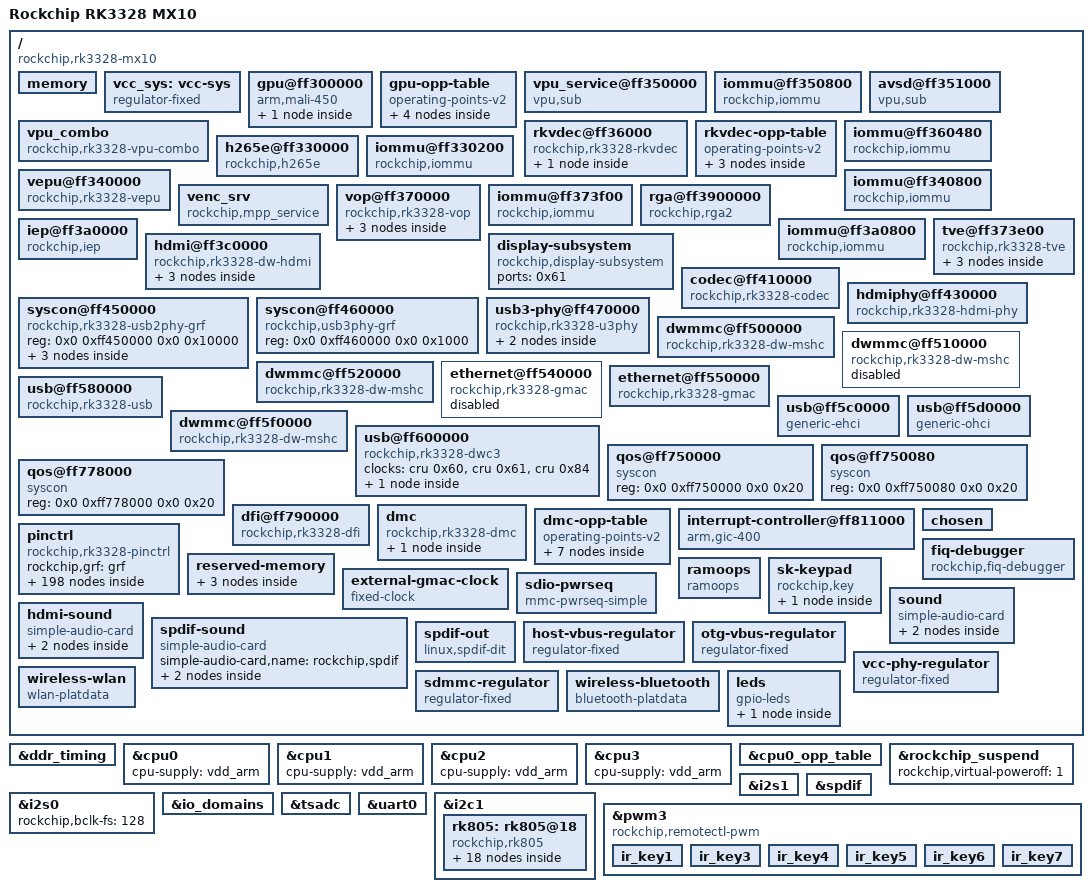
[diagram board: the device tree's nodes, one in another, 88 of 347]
/dts-v1/;

/memreserve/	0x0000000004600000 0x0000000000010000;
/memreserve/	0x0000000004bf0000 0x000000000016c4d8;

#include <dt-bindings/input/input.h>
#include "rk3328_tmp.dtsi"

&ddr_timing {
		ddr3a1_ddr4a9_de-skew = <0x2>;
		ddr3a0_ddr4a10_de-skew = <0x3>;
		ddr3a3_ddr4a6_de-skew = <0x3>;
		ddr3a2_ddr4a4_de-skew = <0x2>;
		ddr3a5_ddr4a8_de-skew = <0x3>;
		ddr3a4_ddr4a5_de-skew = <0x2>;
		ddr3a7_ddr4a11_de-skew = <0x3>;
		ddr3a6_ddr4a7_de-skew = <0x2>;
		ddr3a9_ddr4a0_de-skew = <0x2>;
		ddr3a8_ddr4a13_de-skew = <0x1>;
		ddr3a11_ddr4a3_de-skew = <0x2>;
		ddr3a10_ddr4cs0_de-skew = <0x2>;
		ddr3a13_ddr4a2_de-skew = <0x1>;
		ddr3a12_ddr4ba1_de-skew = <0x2>;
		ddr3a15_ddr4odt0_de-skew = <0x3>;
		ddr3a14_ddr4a1_de-skew = <0x2>;
		ddr3ba1_ddr4a15_de-skew = <0x2>;
		ddr3ba0_ddr4bg0_de-skew = <0x4>;
		ddr3ras_ddr4cke_de-skew = <0x4>;
		ddr3ba2_ddr4ba0_de-skew = <0x3>;
		ddr3we_ddr4bg1_de-skew = <0x2>;
		ddr3cas_ddr4a12_de-skew = <0x2>;
		ddr3ckn_ddr4ckn_de-skew = <0x7>;
		ddr3ckp_ddr4ckp_de-skew = <0x7>;
		ddr3cke_ddr4a16_de-skew = <0x2>;
		ddr3odt0_ddr4a14_de-skew = <0x4>;
		ddr3cs0_ddr4act_de-skew = <0x4>;		
		ddr3reset_ddr4reset_de-skew = <0x7>;
		ddr3cs1_ddr4cs1_de-skew = <0x7>;
		ddr3odt1_ddr4odt1_de-skew = <0x7>;
		cs0_dm0_rx_de-skew = <0xc>;
		cs0_dm0_tx_de-skew = <0xa>;
		cs0_dq0_rx_de-skew = <0xc>;
		cs0_dq0_tx_de-skew = <0xa>;
		cs0_dq1_rx_de-skew = <0xc>;
		cs0_dq1_tx_de-skew = <0xa>;
		cs0_dq2_rx_de-skew = <0xc>;
		cs0_dq2_tx_de-skew = <0xa>;
		cs0_dq3_rx_de-skew = <0xc>;
		cs0_dq3_tx_de-skew = <0xa>;
		cs0_dq4_rx_de-skew = <0xc>;
		cs0_dq4_tx_de-skew = <0xa>;
		cs0_dq5_rx_de-skew = <0xc>;
		cs0_dq5_tx_de-skew = <0xa>;
		cs0_dq6_rx_de-skew = <0xc>;
		cs0_dq6_tx_de-skew = <0xa>;
		cs0_dq7_rx_de-skew = <0xc>;
		cs0_dq7_tx_de-skew = <0xa>;
		cs0_dqs0_rx_de-skew = <0xa>;
		cs0_dqs0p_tx_de-skew = <0xb>;
		cs0_dqs0n_tx_de-skew = <0xb>;
		cs0_dm1_rx_de-skew = <0xa>;
		cs0_dm1_tx_de-skew = <0x8>;
		cs0_dq8_rx_de-skew = <0xa>;
		cs0_dq8_tx_de-skew = <0x8>;
		cs0_dq9_rx_de-skew = <0xa>;
		cs0_dq9_tx_de-skew = <0x8>;
		cs0_dq10_rx_de-skew = <0xa>;
		cs0_dq10_tx_de-skew = <0x8>;
		cs0_dq11_rx_de-skew = <0xa>;
		cs0_dq11_tx_de-skew = <0x8>;
		cs0_dq12_rx_de-skew = <0xa>;
		cs0_dq12_tx_de-skew = <0x8>;
		cs0_dq13_rx_de-skew = <0xa>;
		cs0_dq13_tx_de-skew = <0x8>;
		cs0_dq14_rx_de-skew = <0xa>;
		cs0_dq14_tx_de-skew = <0x8>;
		cs0_dq15_rx_de-skew = <0xa>;
		cs0_dq15_tx_de-skew = <0x8>;
		cs0_dqs1_rx_de-skew = <0x9>;
		cs0_dqs1p_tx_de-skew = <0x8>;
		cs0_dqs1n_tx_de-skew = <0x8>;
		cs0_dm2_rx_de-skew = <0xa>;
		cs0_dm2_tx_de-skew = <0x9>;
		cs0_dq16_rx_de-skew = <0xa>;
		cs0_dq16_tx_de-skew = <0x9>;
		cs0_dq17_rx_de-skew = <0xa>;
		cs0_dq17_tx_de-skew = <0x9>;
		cs0_dq18_rx_de-skew = <0xa>;
		cs0_dq18_tx_de-skew = <0x9>;
		cs0_dq19_rx_de-skew = <0xa>;
		cs0_dq19_tx_de-skew = <0x9>;
		cs0_dq20_rx_de-skew = <0xa>;
		cs0_dq20_tx_de-skew = <0x9>;
		cs0_dq21_rx_de-skew = <0xa>;
		cs0_dq21_tx_de-skew = <0x9>;
		cs0_dq22_rx_de-skew = <0xa>;
		cs0_dq22_tx_de-skew = <0x9>;
		cs0_dq23_rx_de-skew = <0xa>;
		cs0_dq23_tx_de-skew = <0x9>;
		cs0_dqs2_rx_de-skew = <0x9>;
		cs0_dqs2p_tx_de-skew = <0x9>;
		cs0_dqs2n_tx_de-skew = <0x9>;
		cs0_dm3_rx_de-skew = <0x7>;
		cs0_dm3_tx_de-skew = <0x7>;
		cs0_dq24_rx_de-skew = <0x7>;
		cs0_dq24_tx_de-skew = <0x7>;
		cs0_dq25_rx_de-skew = <0x7>;
		cs0_dq25_tx_de-skew = <0x7>;
		cs0_dq26_rx_de-skew = <0x7>;
		cs0_dq26_tx_de-skew = <0x7>;
		cs0_dq27_rx_de-skew = <0x7>;
		cs0_dq27_tx_de-skew = <0x7>;
		cs0_dq28_rx_de-skew = <0x7>;
		cs0_dq28_tx_de-skew = <0x7>;
		cs0_dq29_rx_de-skew = <0x7>;
		cs0_dq29_tx_de-skew = <0x7>;
		cs0_dq30_rx_de-skew = <0x7>;
		cs0_dq30_tx_de-skew = <0x7>;
		cs0_dq31_rx_de-skew = <0x7>;
		cs0_dq31_tx_de-skew = <0x7>;
		cs0_dqs3_rx_de-skew = <0x7>;
		cs0_dqs3p_tx_de-skew = <0x8>;
		cs0_dqs3n_tx_de-skew = <0x8>;
		cs1_dm0_rx_de-skew = <0x7>;
		cs1_dm0_tx_de-skew = <0x8>;
		cs1_dq0_rx_de-skew = <0x7>;
		cs1_dq0_tx_de-skew = <0x8>;
		cs1_dq1_rx_de-skew = <0x7>;
		cs1_dq1_tx_de-skew = <0x8>;
		cs1_dq2_rx_de-skew = <0x7>;
		cs1_dq2_tx_de-skew = <0x8>;
		cs1_dq3_rx_de-skew = <0x7>;
		cs1_dq3_tx_de-skew = <0x8>;
		cs1_dq4_rx_de-skew = <0x7>;
		cs1_dq4_tx_de-skew = <0x8>;
		cs1_dq5_rx_de-skew = <0x7>;
		cs1_dq5_tx_de-skew = <0x8>;
		cs1_dq6_rx_de-skew = <0x7>;
		cs1_dq6_tx_de-skew = <0x8>;
		cs1_dq7_rx_de-skew = <0x7>;
		cs1_dq7_tx_de-skew = <0x8>;
		cs1_dqs0_rx_de-skew = <0x6>;
		cs1_dqs0p_tx_de-skew = <0x9>;
		cs1_dqs0n_tx_de-skew = <0x9>;
		cs1_dm1_rx_de-skew = <0x7>;
		cs1_dm1_tx_de-skew = <0x7>;
		cs1_dq8_rx_de-skew = <0x7>;
		cs1_dq8_tx_de-skew = <0x8>;
		cs1_dq9_rx_de-skew = <0x7>;
		cs1_dq9_tx_de-skew = <0x7>;
		cs1_dq10_rx_de-skew = <0x7>;
		cs1_dq10_tx_de-skew = <0x8>;
		cs1_dq11_rx_de-skew = <0x7>;
		cs1_dq11_tx_de-skew = <0x7>;
		cs1_dq12_rx_de-skew = <0x7>;
		cs1_dq12_tx_de-skew = <0x8>;
		cs1_dq13_rx_de-skew = <0x7>;
		cs1_dq13_tx_de-skew = <0x7>;
		cs1_dq14_rx_de-skew = <0x7>;
		cs1_dq14_tx_de-skew = <0x8>;
		cs1_dq15_rx_de-skew = <0x7>;
		cs1_dq15_tx_de-skew = <0x7>;
		cs1_dqs1_rx_de-skew = <0x7>;
		cs1_dqs1p_tx_de-skew = <0x9>;
		cs1_dqs1n_tx_de-skew = <0x9>;
		cs1_dm2_rx_de-skew = <0x7>;
		cs1_dm2_tx_de-skew = <0x8>;
		cs1_dq16_rx_de-skew = <0x7>;
		cs1_dq16_tx_de-skew = <0x8>;
		cs1_dq17_rx_de-skew = <0x7>;
		cs1_dq17_tx_de-skew = <0x8>;
		cs1_dq18_rx_de-skew = <0x7>;
		cs1_dq18_tx_de-skew = <0x8>;
		cs1_dq19_rx_de-skew = <0x7>;
		cs1_dq19_tx_de-skew = <0x8>;
		cs1_dq20_rx_de-skew = <0x7>;
		cs1_dq20_tx_de-skew = <0x8>;
		cs1_dq21_rx_de-skew = <0x7>;
		cs1_dq21_tx_de-skew = <0x8>;
		cs1_dq22_rx_de-skew = <0x7>;
		cs1_dq22_tx_de-skew = <0x8>;
		cs1_dq23_rx_de-skew = <0x7>;
		cs1_dq23_tx_de-skew = <0x8>;
		cs1_dqs2_rx_de-skew = <0x6>;
		cs1_dqs2p_tx_de-skew = <0x9>;
		cs1_dqs2n_tx_de-skew = <0x9>;
		cs1_dm3_rx_de-skew = <0x7>;
		cs1_dm3_tx_de-skew = <0x7>;
		cs1_dq24_rx_de-skew = <0x7>;
		cs1_dq24_tx_de-skew = <0x8>;
		cs1_dq25_rx_de-skew = <0x7>;
		cs1_dq25_tx_de-skew = <0x7>;
		cs1_dq26_rx_de-skew = <0x7>;
		cs1_dq26_tx_de-skew = <0x7>;
		cs1_dq27_rx_de-skew = <0x7>;
		cs1_dq27_tx_de-skew = <0x7>;
		cs1_dq28_rx_de-skew = <0x7>;
		cs1_dq28_tx_de-skew = <0x7>;
		cs1_dq29_rx_de-skew = <0x7>;
		cs1_dq29_tx_de-skew = <0x7>;
		cs1_dq30_rx_de-skew = <0x7>;
		cs1_dq30_tx_de-skew = <0x7>;
		cs1_dq31_rx_de-skew = <0x7>;
		cs1_dq31_tx_de-skew = <0x7>;
		cs1_dqs3_rx_de-skew = <0x7>;
		cs1_dqs3p_tx_de-skew = <0x9>;
		cs1_dqs3n_tx_de-skew = <0x9>;
};

&cpu0 {
	cpu-supply = <&vdd_arm>;
};

&cpu1 {
	cpu-supply = <&vdd_arm>;
};

&cpu2 {
	cpu-supply = <&vdd_arm>;
};

&cpu3 {
	cpu-supply = <&vdd_arm>;
};

&cpu0_opp_table{
	rockchip,leakage-voltage-sel = <0x1 0x8 0x0 0x9 0xfe 0x1>;
};

&rockchip_suspend {
	rockchip,virtual-poweroff = <1>;
	status = "okay";
};

&i2s0{
	#sound-dai-cells = <0>;
	rockchip,bclk-fs = <128>;
	status = "okay";
};

&i2s1{
	#sound-dai-cells = <0>;
	status = "okay";
};

&spdif {
	#sound-dai-cells = <0>;
	status = "okay";
};

&io_domains {
	status = "okay";
	
	vccio1-supply = <&vcc_io>;
	vccio2-supply = <&vcc18_emmc>;
	vccio3-supply = <&vcc_io>;
	vccio4-supply = <&vcc_18>;		// to be verified!
	vccio5-supply = <&vcc_io>;
	vccio6-supply = <&vcc_io>;
	pmuio-supply = <&vcc_io>;
};

&tsadc{
	status = "okay";
};

&uart0 {
	status = "okay";
};

&i2c1 {
	status = "okay";

	rk805: rk805@18 {
		compatible = "rockchip,rk805";
		status = "okay";
		reg = <0x18>;
		interrupt-parent = <0x3e>;		//interrupt-parent = <&gpio2>;
		interrupts = <0x6 0x8>;
		#clock-cells = <1>;
		clock-output-names = "xin32k", "rk805-clkout2";
		pinctrl-names = "default";
		pinctrl-0 = <0x3f>;			//pinctrl-0 = <&pmic_int_l>;
		wakeup-source;
		gpio-controller;
		#gpio-cells = <2>;

		//vcc1-supply = <&vcc_sys>;
		//vcc2-supply = <&vcc_sys>;
		//vcc3-supply = <&vcc_sys>;
		//vcc4-supply = <&vcc_sys>;
		//vcc5-supply = <&vcc_io>;
		//vcc6-supply = <&vcc_sys>;

		rtc {
			status = "okay";
		};

		pwrkey {
			status = "disabled";
		};
		gpio {
			status = "okay";
		};

		regulators {
			compatible = "rk805-regulator";
			status = "okay";
			#address-cells = <1>;
			#size-cells = <0>;
			
			vdd_logic: RK805_DCDC1 {
				regulator-compatible = "RK805_DCDC1";
				regulator-name = "vdd_logic";
				regulator-min-microvolt = <712500>;
				regulator-max-microvolt = <1450000>;
				regulator-initial-mode = <1>;
				regulator-ramp-delay = <12500>;
				regulator-always-on;
				regulator-boot-on;
				regulator-state-mem {
					regulator-mode = <0x2>;
					regulator-on-in-suspend;
					regulator-suspend-microvolt = <1000000>;
				};
			};

			vdd_arm: RK805_DCDC2 {
				regulator-compatible = "RK805_DCDC2";
				regulator-name = "vdd_arm";
				regulator-init-microvolt = <1225000>;
				regulator-min-microvolt = <712500>;
				regulator-max-microvolt = <1450000>;
				regulator-initial-mode = <0x1>;
				regulator-ramp-delay = <12500>;
				regulator-always-on;
				regulator-boot-on;				
				regulator-state-mem {
					regulator-mode = <0x2>;
					regulator-on-in-suspend;
					regulator-suspend-microvolt = <950000>;
				};
			};
			
			vcc_ddr: RK805_DCDC3 {
				regulator-compatible = "RK805_DCDC3";
				regulator-name = "vcc_ddr";
				regulator-initial-mode = <0x1>;
				regulator-always-on;
				regulator-boot-on;				
				regulator-state-mem {
					regulator-mode = <0x2>;
					regulator-on-in-suspend;
				};
			};

			vcc_io: RK805_DCDC4 {
				regulator-compatible = "RK805_DCDC4";
				regulator-name = "vcc_io";
				regulator-min-microvolt = <3300000>;
				regulator-max-microvolt = <3300000>;
				regulator-initial-mode = <0x1>;
				regulator-always-on;
				regulator-boot-on;				
				regulator-state-mem {
					regulator-mode = <0x2>;
					regulator-on-in-suspend;
					regulator-suspend-microvolt = <3300000>;
				};
			};

			vcc_18: RK805_LDO1 {
				regulator-compatible = "RK805_LDO1";
				regulator-name = "vdd_18";
				regulator-min-microvolt = <1800000>;
				regulator-max-microvolt = <1800000>;
				regulator-always-on;
				regulator-boot-on;				
				regulator-state-mem {
					regulator-on-in-suspend;
					regulator-suspend-microvolt = <1800000>;
				};
			};
			vcc18_emmc: RK805_LDO2 {
				regulator-compatible = "RK805_LDO2";
				regulator-name = "vcc_18emmc";
				regulator-min-microvolt = <1800000>;
				regulator-max-microvolt = <1800000>;
				regulator-always-on;
				regulator-boot-on;				
				regulator-state-mem {
					regulator-on-in-suspend;
					regulator-suspend-microvolt = <1800000>;
				};
			};
			vdd_11: RK805_LDO3 {
				regulator-compatible = "RK805_LDO3";
				regulator-name = "vdd_11";
				regulator-min-microvolt = <1100000>;
				regulator-max-microvolt = <1100000>;
				regulator-boot-on;
				regulator-always-on;
				regulator-state-mem {
					regulator-on-in-suspend;
					regulator-suspend-microvolt = <1100000>;
				};
			};
		};
	};
};

&pwm3 {
	status = "okay";
	compatible = "rockchip,remotectl-pwm";
	remote_pwm_id = <3>;
	handle_cpu_id = <1>;
	remote_support_psci = <1>;

	ir_key1 {
		rockchip,usercode = <0x4040>;
		rockchip,key_table =			//from rk3328-evb.dts
		<0xf2	KEY_REPLY>, 
		<0xba   KEY_BACK>,
		<0xf4   KEY_UP>,
		<0xf1   KEY_DOWN>,
		<0xef   KEY_LEFT>,
		<0xee   KEY_RIGHT>,
		<0xbd   KEY_HOME>,
		<0xea   KEY_VOLUMEUP>,
		<0xe3   KEY_VOLUMEDOWN>,
		<0xe2   KEY_SEARCH>,
		<0xb2   KEY_POWER>,
		<0xbc   KEY_MUTE>,
		<0xec   KEY_MENU>,
		<0xbf   0x190>,
		<0xe0   0x191>,
		<0xe1   0x192>,
		<0xe9   183>,
		<0xe6   248>,
		<0xe8   185>,
		<0xe7   186>,
		<0xf0   388>,
		<0xbe   0x175>;
	};

	ir_key3 {
		rockchip,usercode = <0x1dcc>;
		rockchip,key_table = <0xee 0xe8 0xf0 0x9e 0xf8 0x67 0xbb 0x6c 0xef 0x69 0xed 0x6a 0xfc 0x66 0xf1 0x73 0xfd 0x72 0xb7 0xd9 0xff 0x74 0xf3 0x71 0xbf 0x8b 0xf9 0x191 0xf5 0x192 0xb3 0x184 0xbe 0x2 0xba 0x3 0xb2 0x4 0xbd 0x5 0xf9 0x6 0xb1 0x7 0xfc 0x8 0xf8 0x9 0xb0 0xa 0xb6 0xb 0xb5 0xe>;
	};

	ir_key4 {
		rockchip,usercode = <0xfe01>;
		rockchip,key_table = <0xec 0xe8 0xe6 0x9e 0xe9 0x67 0xe5 0x6c 0xae 0x69 0xaf 0x6a 0xee 0x66 0xe7 0x73 0xef 0x72 0xbf 0x74 0xbe 0x71 0xb3 0x8b 0xff 0x184 0xb1 0x2 0xf2 0x3 0xf3 0x4 0xb5 0x5 0xf6 0x6 0xf7 0x7 0xb9 0x8 0xfa 0x9 0xfb 0xa 0xfe 0xb 0xbd 0xe 0xbc 0xb7 0xf0 0xb8>;
	};

	ir_key5 {
		rockchip,usercode = <0x7f80>;
		rockchip,key_table = <0xec 0xe8 0xd8 0x9e 0xc7 0x67 0xbf 0x6c 0xc8 0x69 0xc6 0x6a 0x8c 0x66 0x78 0x73 0x76 0x72 0x7e 0x74 0xed 0x74 0x7c 0x8b 0xb7 0x184>;
	};

	ir_key6 {
		rockchip,usercode = <0xff00>;
		rockchip,key_table = <0xe5 0x66 0xaf 0x9e 0xb1 0x8b 0xfd 0xe8 0xbc 0x67 0xf5 0x6c 0xf9 0x69 0xf1 0x6a 0xa7 0x72 0xe4 0x73 0xbc 0x71 0xa8 0x74 0xb2 0x184 0xb0 0xb7 0xa4 0xb8 0xa8 0xb9 0xab 0xba 0xb3 0x7b 0xf0 0x7a 0xef 0x2 0xee 0x3 0xed 0x4 0xec 0x5 0xeb 0x74 0xea 0x7 0xe8 0x8 0xe7 0x9 0xe6 0xa 0xe2 0xb 0xf0 0x39 0xe1 0xe>;
	};

	ir_key7 {
		rockchip,usercode = <0x807f>;
		rockchip,key_table = <0x7e 0x74>;
	};
};

/ {
	compatible = "rockchip,rk3328-mx10", "rockchip,rk3328";
	interrupt-parent = <0x1>;
	#address-cells = <0x2>;
	#size-cells = <0x2>;
	model = "Rockchip RK3328 MX10";

	memory {
		reg = <0x0 0x200000 0x0 0x8200000 0x0 0xa200000 0x0 0xf4e00000>;
		device_type = "memory";
	};

	vcc_sys: vcc-sys {
		compatible = "regulator-fixed";
		regulator-name = "vcc_sys";
		regulator-always-on;
		regulator-boot-on;
		regulator-min-microvolt = <5000000>;
		regulator-max-microvolt = <5000000>;
	};

	gpu@ff300000 {
		compatible = "arm,mali-450";
		reg = <0x0 0xff300000 0x0 0x40000 0x0 0xff300000 0x0 0x40000>;
		interrupts = <0x0 0x5a 0x4 0x0 0x57 0x4 0x0 0x5d 0x4 0x0 0x58 0x4 0x0 0x59 0x4 0x0 0x5b 0x4 0x0 0x5c 0x4>;
		interrupt-names = "Mali_GP_IRQ", "Mali_GP_MMU_IRQ", "IRQPP", "Mali_PP0_IRQ", "Mali_PP0_MMU_IRQ", "Mali_PP1_IRQ", "Mali_PP1_MMU_IRQ";
		clocks = <&cru 0x87>;
		clock-names = "clk_mali";
		#cooling-cells = <0x2>;
		operating-points-v2 = <0x4a>;
		status = "okay";
		mali-supply = <&vdd_logic>;
		linux,phandle = <0x31>;
		phandle = <0x31>;

		power_model {
			compatible = "arm,mali-simple-power-model";
			voltage = <0x384>;
			frequency = <0x1f4>;
			static-power = <0x12c>;
			dynamic-power = <0x18c>;
			ts = <0x7d00 0x125c 0xffffffb0 0x2>;
			thermal-zone = "soc-thermal";
		};
	};

	gpu-opp-table {
		compatible = "operating-points-v2";
		rockchip,leakage-voltage-sel = <0x1 0x8 0x0 0x9 0xfe 0x1>;
		nvmem-cells = <&logic_leakage>;
		nvmem-cell-names = "gpu_leakage";
		linux,phandle = <0x4a>;
		phandle = <0x4a>;

		opp-200000000 {
			opp-hz = <0x0 0xbebc200>;
			opp-microvolt = <0xe1d48>;
			opp-microvolt-L0 = <0xe1d48>;
			opp-microvolt-L1 = <0xdbba0>;
		};

		opp-300000000 {
			opp-hz = <0x0 0x11e1a300>;
			opp-microvolt = <0xee098>;
			opp-microvolt-L0 = <0xee098>;
			opp-microvolt-L1 = <0xe7ef0>;
		};

		opp-400000000 {
			opp-hz = <0x0 0x17d78400>;
			opp-microvolt = <0x100590>;
			opp-microvolt-L0 = <0x100590>;
			opp-microvolt-L1 = <0xfa3e8>;
		};

		opp-500000000 {
			opp-hz = <0x0 0x1dcd6500>;
			opp-microvolt = <0x112a88>;
			opp-microvolt-L0 = <0x112a88>;
			opp-microvolt-L1 = <0x10c8e0>;
		};
	};

	vpu_service@ff350000 {
		compatible = "vpu,sub";
		iommu_enabled = <0x1>;
		iommus = <0x4d>;
		allocator = <0x1>;
		reg = <0x0 0xff350000 0x0 0x800>;
		interrupts = <0x0 0x9 0x4>;
		interrupt-names = "irq_dec";
		dev_mode = <0x0>;
		power-domains = <&power 0x8>;
		linux,phandle = <0x4f>;
		phandle = <0x4f>;
	};

	iommu@ff350800 {
		compatible = "rockchip,iommu";
		reg = <0x0 0xff350800 0x0 0x40>;
		interrupts = <0x0 0xb 0x4>;
		interrupt-names = "vpu_mmu";
		clock-names = "aclk", "hclk";
		clocks = <&cru 0x8f &cru 0x146>;
		power-domains = <&power 0x8>;
		#iommu-cells = <0x0>;
		linux,phandle = <0x4d>;
		phandle = <0x4d>;
	};

	avsd@ff351000 {
		compatible = "vpu,sub";
		iommu_enabled = <0x1>;
		iommus = <0x4d>;
		allocator = <0x1>;
		reg = <0x0 0xff351000 0x0 0x200>;
		interrupts = <0x0 0x9 0x4>;
		interrupt-names = "irq_dec";
		power-domains = <&power 0x8>;
		dev_mode = <0x0>;
		linux,phandle = <0x50>;
		phandle = <0x50>;
	};

	vpu_combo {
		compatible = "rockchip,rk3328-vpu-combo", "rockchip,vpu_combo";
		rockchip,grf = <&grf>;
		subcnt = <0x2>;
		rockchip,sub = <0x4f 0x50>;
		clocks = <&cru 0x8f &cru 0x146>;
		clock-names = "aclk_vcodec", "hclk_vcodec";
		resets = <&cru 0xa0 &cru 0xa2>;
		reset-names = "video_a", "video_h";
		mode_bit = <0x0>;
		mode_ctrl = <0x0>;
		power-domains = <&power 0x8>;
		status = "okay";
	};

	rkvdec@ff36000 {
		compatible = "rockchip,rk3328-rkvdec", "rockchip,rkvdec";
		reg = <0x0 0xff360000 0x0 0x400>;
		interrupts = <0x0 0x7 0x4>;
		interrupt-names = "irq_dec";
		clocks = <&cru 0x8b &cru 0x142 &cru 0x41 &cru 0x42>;
		clock-names = "aclk_vcodec", "hclk_vcodec", "clk_cabac", "clk_core";
		resets = <&cru 0xa4 &cru 0xa6 &cru 0xa5 &cru 0xa7 &cru 0xa9 &cru 0xa8>;
		reset-names = "video_a", "video_h", "niu_a", "niu_h", "video_cabac", "video_core";
		rockchip,grf = <&grf>;
		iommus = <0x51>;
		allocator = <0x1>;
		power-domains = <&power 0x5>;
		operating-points-v2 = <0x52>;
		#cooling-cells = <0x2>;
		devfreq = <0x33>;
		status = "okay";
		vcodec-supply = <&vdd_logic>;
		linux,phandle = <0x32>;
		phandle = <0x32>;

		vcodec_power_model {
			compatible = "vcodec_power_model";
			dynamic-power-coefficient = <0x78>;
			static-power-coefficient = <0xc8>;
			ts = <0x7d00 0x125c 0xffffffb0 0x2>;
			thermal-zone = "soc-thermal";
		};
	};

	rkvdec-opp-table {
		compatible = "operating-points-v2";
		rockchip,leakage-voltage-sel = <0x1 0x8 0x0 0x9 0xfe 0x1>;
		nvmem-cells = <&logic_leakage>;
		nvmem-cell-names = "rkvdec_leakage";
		linux,phandle = <0x52>;
		phandle = <0x52>;

		opp-100000000 {
			opp-hz = <0x0 0x5f5e100>;
			opp-microvolt = <0xee098>;
			opp-microvolt-L0 = <0xee098>;
			opp-microvolt-L1 = <0xe7ef0>;
		};

		opp-200000000 {
			opp-hz = <0x0 0xbebc200>;
			opp-microvolt = <0xee098>;
			opp-microvolt-L0 = <0xee098>;
			opp-microvolt-L1 = <0xe7ef0>;
		};

		opp-500000000 {
			opp-hz = <0x0 0x1dcd6500>;
			opp-microvolt = <0x106738>;
			opp-microvolt-L0 = <0x106738>;
			opp-microvolt-L1 = <0x100590>;
		};
	};

	iommu@ff360480 {
		compatible = "rockchip,iommu";
		reg = <0x0 0xff360480 0x0 0x40 0x0 0xff3604c0 0x0 0x40>;
		interrupts = <0x0 0x4a 0x4>;
		interrupt-names = "rkvdec_mmu";
		clocks = <&cru 0x8b &cru 0x142>;
		clock-names = "aclk_vcodec", "hclk_vcodec";
		power-domains = <&power 0x5>;
		#iommu-cells = <0x0>;
		linux,phandle = <0x51>;
		phandle = <0x51>;
	};

	h265e@ff330000 {
		compatible = "rockchip,h265e";
		rockchip,grf = <&grf>;
		iommu_enabled = <0x1>;
		iommus = <0x53>;
		reg = <0x0 0xff330000 0x0 0x200>;
		interrupts = <0x0 0x5f 0x4>;
		clocks = <&cru 0x93 &cru 0xdd &cru 0x44 &cru 0x43 &cru 0x8c &cru 0x82>;
		clock-names = "aclk_h265", "pclk_h265", "clk_core", "clk_dsp", "aclk_venc", "aclk_axi2sram";
		rockchip,srv = <0x54>;
		mode_bit = <0xb>;
		mode_ctrl = <0x40c>;
		allocator = <0x1>;
		power-domains = <&power 0x6>;
		status = "okay";
	};

	iommu@ff330200 {
		compatible = "rockchip,iommu";
		reg = <0x0 0xff330200 0x0 0x100>;
		interrupts = <0x0 0x60 0x4>;
		interrupt-names = "h265e_mmu";
		clocks = <&cru 0x93 &cru 0xdd>;
		clock-names = "aclk", "hclk";
		power-domains = <&power 0x6>;
		#iommu-cells = <0x0>;
		linux,phandle = <0x53>;
		phandle = <0x53>;
	};

	vepu@ff340000 {
		compatible = "rockchip,rk3328-vepu", "rockchip,vepu";
		rockchip,grf = <&grf>;
		iommu_enabled = <0x1>;
		iommus = <0x55>;
		reg = <0x0 0xff340000 0x0 0x400>;
		interrupts = <0x0 0x61 0x4>;
		clocks = <&cru 0x94 &cru 0x14a &cru 0x44>;
		clock-names = "aclk_vcodec", "hclk_vcodec", "clk_core";
		resets = <&cru 0xb7 &cru 0xb6>;
		reset-names = "video_h", "video_a";
		rockchip,srv = <0x54>;
		mode_bit = <0xb>;
		mode_ctrl = <0x40c>;
		allocator = <0x1>;
		power-domains = <&power 0x6>;
		status = "okay";
	};

	iommu@ff340800 {
		compatible = "rockchip,iommu";
		reg = <0x0 0xff340800 0x0 0x40>;
		interrupts = <0x0 0x62 0x4>;
		interrupt-names = "vepu_mmu";
		clocks = <&cru 0x94 &cru 0x14a>;
		clock-names = "aclk", "hclk";
		power-domains = <&power 0x6>;
		#iommu-cells = <0x0>;
		linux,phandle = <0x55>;
		phandle = <0x55>;
	};

	venc_srv {
		compatible = "rockchip,mpp_service";
		linux,phandle = <0x54>;
		phandle = <0x54>;
	};

	vop@ff370000 {
		compatible = "rockchip,rk3328-vop";
		reg = <0x0 0xff370000 0x0 0x3efc>;
		interrupts = <0x0 0x20 0x4>;
		clocks = <&cru 0x91 &cru 0x78 &cru 0x13b>;
		clock-names = "aclk_vop", "dclk_vop", "hclk_vop";
		resets = <&cru 0x85 &cru 0x86 &cru 0x87>;
		reset-names = "axi", "ahb", "dclk";
		iommus = <0x56>;
		status = "okay";

		port {
			#address-cells = <0x1>;
			#size-cells = <0x0>;
			linux,phandle = <0x61>;
			phandle = <0x61>;

			endpoint@0 {
				reg = <0x0>;
				remote-endpoint = <0x57>;
				linux,phandle = <0x5f>;
				phandle = <0x5f>;
			};

			endpoint@1 {
				reg = <0x1>;
				remote-endpoint = <0x58>;
				linux,phandle = <0x60>;
				phandle = <0x60>;
			};
		};
	};

	iommu@ff373f00 {
		compatible = "rockchip,iommu";
		reg = <0x0 0xff373f00 0x0 0x100>;
		interrupts = <0x0 0x20 0x4>;
		interrupt-names = "vop_mmu";
		clocks = <&cru 0x91 &cru 0x13b>;
		clock-names = "aclk", "hclk";
		#iommu-cells = <0x0>;
		status = "okay";
		linux,phandle = <0x56>;
		phandle = <0x56>;
	};

	rga@ff3900000 {
		compatible = "rockchip,rga2";
		dev_mode = <0x1>;
		reg = <0x0 0xff390000 0x0 0x1000>;
		interrupts = <0x0 0x21 0x4>;
		clocks = <&cru 0x9a &cru 0x154 &cru 0x45>;
		clock-names = "aclk_rga", "hclk_rga", "clk_rga";
		dma-coherent;
		status = "okay";
	};

	iep@ff3a0000 {
		compatible = "rockchip,iep";
		iommu_enabled = <0x1>;
		iommus = <0x59>;
		reg = <0x0 0xff3a0000 0x0 0x800>;
		interrupts = <0x0 0x1f 0x4>;
		clocks = <&cru 0x9b &cru 0x153>;
		clock-names = "aclk_iep", "hclk_iep";
		power-domains = <&power 0x5>;
		allocator = <0x1>;
		version = <0x2>;
		status = "okay";
	};

	iommu@ff3a0800 {
		compatible = "rockchip,iommu";
		reg = <0x0 0xff3a0800 0x0 0x40>;
		interrupts = <0x0 0x1f 0x4>;
		interrupt-names = "iep_mmu";
		clocks = <&cru 0x9b &cru 0x153>;
		clock-names = "aclk", "hclk";
		power-domains = <&power 0x5>;
		#iommu-cells = <0x0>;
		status = "okay";
		linux,phandle = <0x59>;
		phandle = <0x59>;
	};

	hdmi@ff3c0000 {
		compatible = "rockchip,rk3328-dw-hdmi";
		reg = <0x0 0xff3c0000 0x0 0x20000>;
		reg-io-width = <0x4>;
		interrupts = <0x0 0x23 0x4 0x0 0x47 0x4>;
		clocks = <&cru 0xe7 &cru 0x46 &cru 0x1e &cru 0x147>;
		clock-names = "iahb", "isfr", "cec", "hclk_vio";
		phys = <0x5a>;
		phy-names = "hdmi_phy";
		pinctrl-names = "default", "gpio";
		pinctrl-0 = <0x5b 0x5c 0x5d>;
		pinctrl-1 = <0x5e>;
		resets = <&cru 0x8f &cru 0x51>;
		reset-names = "hdmi", "hdmiphy";
		rockchip,grf = <&grf>;
		status = "okay";
		#sound-dai-cells = <0x0>;
		ddc-i2c-scl-high-time-ns = <0x2599>;
		ddc-i2c-scl-low-time-ns = <0x2710>;
		linux,phandle = <0x93>;
		phandle = <0x93>;

		ports {

			port {
				#address-cells = <0x1>;
				#size-cells = <0x0>;

				endpoint@0 {
					reg = <0x0>;
					remote-endpoint = <0x5f>;
					linux,phandle = <0x57>;
					phandle = <0x57>;
				};
			};
		};
	};

	tve@ff373e00 {
		compatible = "rockchip,rk3328-tve";
		reg = <0x0 0xff373e00 0x0 0x100 0x0 0xff420000 0x0 0x10000>;
		rockchip,saturation = <0x376749>;
		rockchip,brightcontrast = <0xa305>;
		rockchip,adjtiming = <0xb6c00880>;
		rockchip,lumafilter0 = <0x1ff0000>;
		rockchip,lumafilter1 = <0xf40200fe>;
		rockchip,lumafilter2 = <0xf332d70c>;
		rockchip,daclevel = <0x22>;
		rockchip,dac1level = <0x7>;
		status = "okay";

		ports {

			port {
				#address-cells = <0x1>;
				#size-cells = <0x0>;

				endpoint@0 {
					reg = <0x0>;
					remote-endpoint = <0x60>;
					linux,phandle = <0x58>;
					phandle = <0x58>;
				};
			};
		};
	};

	display-subsystem {
		compatible = "rockchip,display-subsystem";
		ports = <0x61>;
		status = "okay";
	};

	codec@ff410000 {
		compatible = "rockchip,rk3328-codec";
		reg = <0x0 0xff410000 0x0 0x1000>;
		rockchip,grf = <&grf>;
		clocks = <&cru 0xeb &cru 0x2a>;
		clock-names = "pclk", "mclk";
		status = "okay";
		#sound-dai-cells = <0x0>;
		linux,phandle = <0x91>;
		phandle = <0x91>;
	};

	hdmiphy@ff430000 {
		compatible = "rockchip,rk3328-hdmi-phy";
		reg = <0x0 0xff430000 0x0 0x10000>;
		interrupts = <0x0 0x53 0x4>;
		#phy-cells = <0x0>;
		clocks = <&cru 0xe4>, <&xin24m>;
		clock-names = "sysclk", "refclk";
		#clock-cells = <0x0>;
		clock-output-names = "hdmi_phy";
		status = "okay";
		linux,phandle = <0x5a>;
		phandle = <0x5a>;
	};

	syscon@ff450000 {
		compatible = "rockchip,rk3328-usb2phy-grf", "syscon", "simple-mfd";
		reg = <0x0 0xff450000 0x0 0x10000>;
		#address-cells = <0x1>;
		#size-cells = <0x1>;

		usb2-phy@100 {
			compatible = "rockchip,rk3328-usb2phy";
			reg = <0x100 0x10>;
			clocks = <&xin24m>;
			clock-names = "phyclk";
			#clock-cells = <0x0>;
			assigned-clocks = <&cru 0x7b>;
			assigned-clock-parents = <0x65>;
			clock-output-names = "usb480m_phy";
			status = "okay";
			linux,phandle = <0x65>;
			phandle = <0x65>;

			host-port {
				#phy-cells = <0x0>;
				interrupts = <0x0 0x3e 0x4>;
				interrupt-names = "linestate";
				status = "okay";
				linux,phandle = <0x78>;
				phandle = <0x78>;
			};

			otg-port {
				#phy-cells = <0x0>;
				interrupts = <0x0 0x3b 0x4 0x0 0x3c 0x4 0x0 0x3d 0x4>;
				interrupt-names = "otg-bvalid", "otg-id", "linestate";
				status = "okay";
				vbus-supply = <0x66>;
				linux,phandle = <0x77>;
				phandle = <0x77>;
			};
		};
	};

	syscon@ff460000 {
		compatible = "rockchip,usb3phy-grf", "syscon";
		reg = <0x0 0xff460000 0x0 0x1000>;
		linux,phandle = <0x67>;
		phandle = <0x67>;
	};

	usb3-phy@ff470000 {
		compatible = "rockchip,rk3328-u3phy";
		reg = <0x0 0xff470000 0x0 0x0>;
		rockchip,u3phygrf = <0x67>;
		rockchip,grf = <&grf>;
		interrupts = <0x0 0x4d 0x4>;
		interrupt-names = "linestate";
		clocks = <&cru 0xe0 &cru 0xe1>;
		clock-names = "u3phy-otg", "u3phy-pipe";
		resets = <&cru 0x7d &cru 0x7e &cru 0x7f &cru 0x7c &cru 0x9e &cru 0x9f>;
		reset-names = "u3phy-u2-por", "u3phy-u3-por", "u3phy-pipe-mac", "u3phy-utmi-mac", "u3phy-utmi-apb", "u3phy-pipe-apb";
		#address-cells = <0x2>;
		#size-cells = <0x2>;
		ranges;
		status = "okay";
		vbus-supply = <0x68>;

		utmi@ff470000 {
			reg = <0x0 0xff470000 0x0 0x8000>;
			#phy-cells = <0x0>;
			status = "okay";
			linux,phandle = <0x7d>;
			phandle = <0x7d>;
		};

		pipe@ff478000 {
			reg = <0x0 0xff478000 0x0 0x8000>;
			#phy-cells = <0x0>;
			status = "okay";
			linux,phandle = <0x7e>;
			phandle = <0x7e>;
		};
	};

	dwmmc@ff500000 {
		compatible = "rockchip,rk3328-dw-mshc", "rockchip,rk3288-dw-mshc";
		reg = <0x0 0xff500000 0x0 0x4000>;
		clock-freq-min-max = <0x61a80 0x8f0d180>;
		clocks = <&cru 0x13d &cru 0x21 &cru 0x4a &cru 0x4e>;
		clock-names = "biu", "ciu", "ciu-drv", "ciu-sample";
		fifo-depth = <0x100>;
		interrupts = <0x0 0xc 0x4>;
		status = "okay";
		bus-width = <0x4>;
		cap-mmc-highspeed;
		cap-sd-highspeed;
		disable-wp;
		max-frequency = <0x8f0d180>;
		num-slots = <0x1>;
		pinctrl-names = "default";
		pinctrl-0 = <0x69 0x6a 0x6b 0x6c>;
		supports-sd;
		vmmc-supply = <0x6d>;
	};

	dwmmc@ff510000 {
		compatible = "rockchip,rk3328-dw-mshc", "rockchip,rk3288-dw-mshc";
		reg = <0x0 0xff510000 0x0 0x4000>;
		clock-freq-min-max = <0x61a80 0x8f0d180>;
		clocks = <&cru 0x13e &cru 0x22 &cru 0x4b &cru 0x4f>;
		clock-names = "biu", "ciu", "ciu-drv", "ciu-sample";
		fifo-depth = <0x100>;
		interrupts = <0x0 0xd 0x4>;
		status = "disabled";
	};

	dwmmc@ff520000 {
		compatible = "rockchip,rk3328-dw-mshc", "rockchip,rk3288-dw-mshc";
		reg = <0x0 0xff520000 0x0 0x4000>;
		clock-freq-min-max = <0x61a80 0x8f0d180>;
		clocks = <&cru 0x13f &cru 0x23 &cru 0x4c &cru 0x50>;
		clock-names = "biu", "ciu", "ciu-drv", "ciu-sample";
		fifo-depth = <0x100>;
		interrupts = <0x0 0xe 0x4>;
		status = "okay";
		bus-width = <0x8>;
		cap-mmc-highspeed;
		mmc-hs200-1_8v;
		supports-emmc;
		disable-wp;
		non-removable;
		num-slots = <0x1>;
		pinctrl-names = "default";
		pinctrl-0 = <0x6e 0x6f 0x70>;
	};

	ethernet@ff540000 {
		compatible = "rockchip,rk3328-gmac";
		reg = <0x0 0xff540000 0x0 0x10000>;
		rockchip,grf = <&grf>;
		interrupts = <0x0 0x18 0x4>;
		interrupt-names = "macirq";
		clocks = <&cru 0x64 &cru 0x57 &cru 0x58 &cru 0x5a &cru 0x59 &cru 0x96 &cru 0xdf>;
		clock-names = "stmmaceth", "mac_clk_rx", "mac_clk_tx", "clk_mac_ref", "clk_mac_refout", "aclk_mac", "pclk_mac";
		resets = <&cru 0x63>;
		reset-names = "stmmaceth";
		status = "disabled";
		phy-supply = <0x71>;
		phy-mode = "rgmii";
		clock_in_out = "input";
		snps,reset-gpio = <0x72 0x12 0x1>;
		snps,reset-active-low;
		snps,reset-delays-us = <0x0 0x2710 0xc350>;
		assigned-clocks = <&cru 0x64 &cru 0x66>;
		assigned-clock-parents = <0x73 0x73>;
		pinctrl-names = "default";
		pinctrl-0 = <0x74>;
		tx_delay = <0x26>;
		rx_delay = <0x11>;
	};

	ethernet@ff550000 {
		compatible = "rockchip,rk3328-gmac";
		reg = <0x0 0xff550000 0x0 0x10000>;
		rockchip,grf = <&grf>;
		interrupts = <0x0 0x15 0x4>;
		interrupt-names = "macirq";
		clocks = <&cru 0x54 &cru 0x53 &cru 0x53 &cru 0x55 &cru 0x95 &cru 0xde &cru 0x56>;
		clock-names = "stmmaceth", "mac_clk_rx", "mac_clk_tx", "clk_mac_ref", "aclk_mac", "pclk_mac", "clk_macphy";
		resets = <&cru 0x62 &cru 0x64>;
		reset-names = "stmmaceth", "mac-phy";
		phy-mode = "rmii";
		phy-is-integrated;
		pinctrl-names = "default";
		pinctrl-0 = <0x75 0x76>;
		status = "okay";
		phy-supply = <0x71>;
		clock_in_out = "output";
		assigned-clocks = <&cru 0x65>;
		assigned-clock-rate = <0x2faf080>;
		assigned-clock-parents = <&cru 0x54>;
	};

	usb@ff580000 {
		compatible = "rockchip,rk3328-usb", "rockchip,rk3066-usb", "snps,dwc2";
		reg = <0x0 0xff580000 0x0 0x40000>;
		interrupts = <0x0 0x17 0x4>;
		clocks = <&cru 0x14d &cru 0x14c>;
		clock-names = "otg", "otg_pmu";
		dr_mode = "host";
		g-np-tx-fifo-size = <0x10>;
		g-rx-fifo-size = <0x113>;
		g-tx-fifo-size = <0x100 0x80 0x80 0x40 0x40 0x20>;
		g-use-dma;
		phys = <0x77>;
		phy-names = "usb2-phy";
		status = "okay";
	};

	usb@ff5c0000 {
		compatible = "generic-ehci";
		reg = <0x0 0xff5c0000 0x0 0x10000>;
		interrupts = <0x0 0x10 0x4>;
		clocks = <&cru 0x14e &cru 0x14f 0x65>;
		clock-names = "usbhost", "arbiter", "utmi";
		phys = <0x78>;
		phy-names = "usb";
		status = "okay";
	};

	usb@ff5d0000 {
		compatible = "generic-ohci";
		reg = <0x0 0xff5d0000 0x0 0x10000>;
		interrupts = <0x0 0x11 0x4>;
		clocks = <&cru 0x14e &cru 0x14f 0x65>;
		clock-names = "usbhost", "arbiter", "utmi";
		phys = <0x78>;
		phy-names = "usb";
		status = "okay";
	};

	dwmmc@ff5f0000 {
		compatible = "rockchip,rk3328-dw-mshc", "rockchip,rk3288-dw-mshc";
		reg = <0x0 0xff5f0000 0x0 0x4000>;
		clock-freq-min-max = <0x61a80 0x8f0d180>;
		clocks = <&cru 0x140 &cru 0x1f &cru 0x4d &cru 0x51>;
		clock-names = "biu", "ciu", "ciu-drv", "ciu-sample";
		fifo-depth = <0x100>;
		interrupts = <0x0 0x4 0x4>;
		status = "okay";
		bus-width = <0x4>;
		cap-sd-highspeed;
		cap-sdio-irq;
		disable-wp;
		keep-power-in-suspend;
		max-frequency = <0x17d7840>;
		mmc-pwrseq = <0x79>;
		non-removable;
		num-slots = <0x1>;
		pinctrl-names = "default";
		pinctrl-0 = <0x7a 0x7b 0x7c>;
		supports-sdio;
		sd-uhs-sdr104;
	};

	usb@ff600000 {
		compatible = "rockchip,rk3328-dwc3";
		clocks = <&cru 0x60 &cru 0x61 &cru 0x84>;
		clock-names = "ref_clk", "suspend_clk", "bus_clk";
		#address-cells = <0x2>;
		#size-cells = <0x2>;
		ranges;
		status = "okay";

		dwc3@ff600000 {
			compatible = "snps,dwc3";
			reg = <0x0 0xff600000 0x0 0x100000>;
			interrupts = <0x0 0x43 0x4>;
			dr_mode = "host";
			phys = <0x7d 0x7e>;
			phy-names = "usb2-phy", "usb3-phy";
			phy_type = "utmi_wide";
			snps,dis_enblslpm_quirk;
			snps,dis-u2-freeclk-exists-quirk;
			snps,dis_u2_susphy_quirk;
			snps,dis-u3-autosuspend-quirk;
			snps,dis_u3_susphy_quirk;
			snps,dis-del-phy-power-chg-quirk;
			snps,tx-ipgap-linecheck-dis-quirk;
			status = "okay";
		};
	};

	qos@ff750000 {
		compatible = "syscon";
		reg = <0x0 0xff750000 0x0 0x20>;
		linux,phandle = <0x2c>;
		phandle = <0x2c>;
	};

	qos@ff750080 {
		compatible = "syscon";
		reg = <0x0 0xff750080 0x0 0x20>;
		linux,phandle = <0x2d>;
		phandle = <0x2d>;
	};

	qos@ff778000 {
		compatible = "syscon";
		reg = <0x0 0xff778000 0x0 0x20>;
		linux,phandle = <0x2e>;
		phandle = <0x2e>;
	};

	dfi@ff790000 {
		reg = <0x0 0xff790000 0x0 0x400>;
		compatible = "rockchip,rk3328-dfi";
		rockchip,grf = <&grf>;
		status = "okay";
		linux,phandle = <0x7f>;
		phandle = <0x7f>;
	};

	dmc {
		compatible = "rockchip,rk3328-dmc";
		devfreq-events = <0x7f>;
		clocks = <&cru 0x40>;
		clock-names = "dmc_clk";
		operating-points-v2 = <0x80>;
		ddr_timing = <&ddr_timing>;
		upthreshold = <0x28>;
		downdifferential = <0x14>;
		system-status-freq = <0x1 0xbfe50 0x8 0xbfe50 0x2 0xbfe50 0x20 0xbfe50 0x10 0xbfe50 0x10000 0xe3c88 0x2000 0xe3c88 0x1000 0xe3c88>;
		auto-min-freq = <0xbfe50>;
		auto-freq-en = <0x0>;
		#cooling-cells = <0x2>;
		status = "okay";
		center-supply = <&vdd_logic>;
		linux,phandle = <0x33>;
		phandle = <0x33>;

		ddr_power_model {
			compatible = "ddr_power_model";
			dynamic-power-coefficient = <0x78>;
			static-power-coefficient = <0xc8>;
			ts = <0x7d00 0x125c 0xffffffb0 0x2>;
			thermal-zone = "soc-thermal";
		};
	};

	dmc-opp-table {
		compatible = "operating-points-v2";
		rockchip,leakage-voltage-sel = <0x1 0x8 0x0 0x9 0xfe 0x1>;
		nvmem-cells = <&logic_leakage>;
		nvmem-cell-names = "ddr_leakage";
		linux,phandle = <0x80>;
		phandle = <0x80>;

		opp-400000000 {
			opp-hz = <0x0 0x17d78400>;
			opp-microvolt = <0xe1d48>;
			opp-microvolt-L0 = <0xe1d48>;
			opp-microvolt-L1 = <0xdbba0>;
			status = "disabled";
		};

		opp-600000000 {
			opp-hz = <0x0 0x23c34600>;
			opp-microvolt = <0xfa3e8>;
			opp-microvolt-L0 = <0xfa3e8>;
			opp-microvolt-L1 = <0xf4240>;
			status = "disabled";
		};

		opp-786000000 {
			opp-hz = <0x0 0x2ed96880>;
			opp-microvolt = <0x11edd8>;
			opp-microvolt-L0 = <0x11edd8>;
			opp-microvolt-L1 = <0x118c30>;
		};

		opp-800000000 {
			opp-hz = <0x0 0x2faf0800>;
			opp-microvolt = <0x11edd8>;
			opp-microvolt-L0 = <0x11edd8>;
			opp-microvolt-L1 = <0x118c30>;
		};

		opp-850000000 {
			opp-hz = <0x0 0x32a9f880>;
			opp-microvolt = <0x106738>;
			opp-microvolt-L0 = <0x106738>;
			opp-microvolt-L1 = <0x100590>;
			status = "disabled";
		};

		opp-933000000 {
			opp-hz = <0x0 0x379c7340>;
			opp-microvolt = <0x10c8e0>;
			opp-microvolt-L0 = <0x10c8e0>;
			opp-microvolt-L1 = <0x106738>;
			status = "disabled";
		};

		opp-1066000000 {
			opp-hz = <0x0 0x3f89de80>;
			opp-microvolt = <0x11edd8>;
			opp-microvolt-L0 = <0x11edd8>;
			opp-microvolt-L1 = <0x118c30>;
			status = "disabled";
		};
	};

	interrupt-controller@ff811000 {
		compatible = "arm,gic-400";
		#interrupt-cells = <0x3>;
		#address-cells = <0x0>;
		interrupt-controller;
		reg = <0x0 0xff811000 0x0 0x1000 0x0 0xff812000 0x0 0x2000 0x0 0xff814000 0x0 0x2000 0x0 0xff816000 0x0 0x2000>;
		interrupts = <0x1 0x9 0xf04>;
		linux,phandle = <0x1>;
		phandle = <0x1>;
	};

	pinctrl {
		compatible = "rockchip,rk3328-pinctrl";
		rockchip,grf = <&grf>;
		#address-cells = <0x2>;
		#size-cells = <0x2>;
		ranges;

		gpio0@ff210000 {
			compatible = "rockchip,gpio-bank";
			reg = <0x0 0xff210000 0x0 0x100>;
			interrupts = <0x0 0x33 0x4>;
			clocks = <&cru 0xc8>;
			gpio-controller;
			#gpio-cells = <0x2>;
			interrupt-controller;
			#interrupt-cells = <0x2>;
			linux,phandle = <0x96>;
			phandle = <0x96>;
		};

		gpio1@ff220000 {
			compatible = "rockchip,gpio-bank";
			reg = <0x0 0xff220000 0x0 0x100>;
			interrupts = <0x0 0x34 0x4>;
			clocks = <&cru 0xc9>;
			gpio-controller;
			#gpio-cells = <0x2>;
			interrupt-controller;
			#interrupt-cells = <0x2>;
			linux,phandle = <0x72>;
			phandle = <0x72>;
		};

		gpio2@ff230000 {
			compatible = "rockchip,gpio-bank";
			reg = <0x0 0xff230000 0x0 0x100>;
			interrupts = <0x0 0x35 0x4>;
			clocks = <&cru 0xca>;
			gpio-controller;
			#gpio-cells = <0x2>;
			interrupt-controller;
			#interrupt-cells = <0x2>;
			linux,phandle = <0x3e>;
			phandle = <0x3e>;
		};

		gpio3@ff240000 {
			compatible = "rockchip,gpio-bank";
			reg = <0x0 0xff240000 0x0 0x100>;
			interrupts = <0x0 0x36 0x4>;
			clocks = <&cru 0xcb>;
			gpio-controller;
			#gpio-cells = <0x2>;
			interrupt-controller;
			#interrupt-cells = <0x2>;
			linux,phandle = <0x8f>;
			phandle = <0x8f>;
		};

		pcfg-pull-up {
			bias-pull-up;
			linux,phandle = <0x83>;
			phandle = <0x83>;
		};

		pcfg-pull-down {
			bias-pull-down;
			linux,phandle = <0x8c>;
			phandle = <0x8c>;
		};

		pcfg-pull-none {
			bias-disable;
			linux,phandle = <0x82>;
			phandle = <0x82>;
		};

		pcfg-pull-none-2ma {
			bias-disable;
			drive-strength = <0x2>;
			linux,phandle = <0x8b>;
			phandle = <0x8b>;
		};

		pcfg-pull-up-2ma {
			bias-pull-up;
			drive-strength = <0x2>;
		};

		pcfg-pull-up-4ma {
			bias-pull-up;
			drive-strength = <0x4>;
			linux,phandle = <0x85>;
			phandle = <0x85>;
		};

		pcfg-pull-none-4ma {
			bias-disable;
			drive-strength = <0x4>;
			linux,phandle = <0x86>;
			phandle = <0x86>;
		};

		pcfg-pull-down-4ma {
			bias-pull-down;
			drive-strength = <0x4>;
		};

		pcfg-pull-none-8ma {
			bias-disable;
			drive-strength = <0x8>;
			linux,phandle = <0x87>;
			phandle = <0x87>;
		};

		pcfg-pull-up-8ma {
			bias-pull-up;
			drive-strength = <0x8>;
			linux,phandle = <0x88>;
			phandle = <0x88>;
		};

		pcfg-pull-none-12ma {
			bias-disable;
			drive-strength = <0xc>;
			linux,phandle = <0x89>;
			phandle = <0x89>;
		};

		pcfg-pull-up-12ma {
			bias-pull-up;
			drive-strength = <0xc>;
			linux,phandle = <0x8a>;
			phandle = <0x8a>;
		};

		pcfg-output-high {
			output-high;
		};

		pcfg-output-low {
			output-low;
		};

		pcfg-input-high {
			bias-pull-up;
			input-enable;
			linux,phandle = <0x84>;
			phandle = <0x84>;
		};

		pcfg-input {
			input-enable;
		};

		i2c0 {

			i2c0-xfer {
				rockchip,pins = <0x2 0x18 0x1 0x82 0x2 0x19 0x1 0x82>;
				linux,phandle = <0x3c>;
				phandle = <0x3c>;
			};
		};

		i2c1 {

			i2c1-xfer {
				rockchip,pins = <0x2 0x4 0x2 0x82 0x2 0x5 0x2 0x82>;
				linux,phandle = <0x3d>;
				phandle = <0x3d>;
			};
		};

		i2c2 {

			i2c2-xfer {
				rockchip,pins = <0x2 0xd 0x1 0x82 0x2 0xe 0x1 0x82>;
				linux,phandle = <0x40>;
				phandle = <0x40>;
			};
		};

		i2c3 {

			i2c3-xfer {
				rockchip,pins = <0x0 0x5 0x2 0x82 0x0 0x6 0x2 0x82>;
				linux,phandle = <0x41>;
				phandle = <0x41>;
			};

			i2c3-gpio {
				rockchip,pins = <0x0 0x5 0x0 0x82 0x0 0x6 0x0 0x82>;
				linux,phandle = <0x5e>;
				phandle = <0x5e>;
			};
		};

		tsp {

			tsp-d0 {
				rockchip,pins = <0x3 0x4 0x1 0x82>;
				linux,phandle = <0x1d>;
				phandle = <0x1d>;
			};

			tsp-d1 {
				rockchip,pins = <0x3 0x5 0x1 0x82>;
				linux,phandle = <0x1e>;
				phandle = <0x1e>;
			};

			tsp-d2 {
				rockchip,pins = <0x3 0x6 0x1 0x82>;
				linux,phandle = <0x1f>;
				phandle = <0x1f>;
			};

			tsp-d3 {
				rockchip,pins = <0x3 0x7 0x1 0x82>;
				linux,phandle = <0x20>;
				phandle = <0x20>;
			};

			tsp-d4 {
				rockchip,pins = <0x3 0x8 0x1 0x82>;
				linux,phandle = <0x21>;
				phandle = <0x21>;
			};

			tsp-d5 {
				rockchip,pins = <0x2 0x10 0x3 0x82>;
				linux,phandle = <0x22>;
				phandle = <0x22>;
			};

			tsp-d6 {
				rockchip,pins = <0x2 0x11 0x3 0x82>;
				linux,phandle = <0x23>;
				phandle = <0x23>;
			};

			tsp-d7 {
				rockchip,pins = <0x2 0x12 0x3 0x82>;
				linux,phandle = <0x24>;
				phandle = <0x24>;
			};

			tsp-sync {
				rockchip,pins = <0x2 0xf 0x3 0x82>;
				linux,phandle = <0x25>;
				phandle = <0x25>;
			};

			tsp-clk {
				rockchip,pins = <0x3 0x2 0x1 0x82>;
				linux,phandle = <0x26>;
				phandle = <0x26>;
			};

			tsp-fail {
				rockchip,pins = <0x3 0x1 0x1 0x82>;
				linux,phandle = <0x27>;
				phandle = <0x27>;
			};

			tsp-valid {
				rockchip,pins = <0x3 0x0 0x1 0x82>;
				linux,phandle = <0x28>;
				phandle = <0x28>;
			};
		};

		hdmi_i2c {

			hdmii2c-xfer {
				rockchip,pins = <0x0 0x5 0x1 0x82 0x0 0x6 0x1 0x82>;
				linux,phandle = <0x5c>;
				phandle = <0x5c>;
			};
		};

		tsadc {

			otp-gpio {
				rockchip,pins = <0x2 0xd 0x0 0x82>;
				linux,phandle = <0x34>;
				phandle = <0x34>;
			};

			otp-out {
				rockchip,pins = <0x2 0xd 0x1 0x82>;
				linux,phandle = <0x35>;
				phandle = <0x35>;
			};
		};

		uart0 {

			uart0-xfer {
				rockchip,pins = <0x1 0x9 0x1 0x83 0x1 0x8 0x1 0x82>;
				linux,phandle = <0x36>;
				phandle = <0x36>;
			};

			uart0-cts {
				rockchip,pins = <0x1 0xb 0x1 0x82>;
				linux,phandle = <0x37>;
				phandle = <0x37>;
			};

			uart0-rts {
				rockchip,pins = <0x1 0xa 0x1 0x82>;
				linux,phandle = <0x9b>;
				phandle = <0x9b>;
			};

			uart0-rts-gpio {
				rockchip,pins = <0x1 0xa 0x0 0x82>;
			};
		};

		uart1 {

			uart1-xfer {
				rockchip,pins = <0x3 0x4 0x4 0x83 0x3 0x6 0x4 0x82>;
				linux,phandle = <0x38>;
				phandle = <0x38>;
			};

			uart1-cts {
				rockchip,pins = <0x3 0x7 0x4 0x82>;
				linux,phandle = <0x39>;
				phandle = <0x39>;
			};

			uart1-rts {
				rockchip,pins = <0x3 0x5 0x4 0x82>;
				linux,phandle = <0x3a>;
				phandle = <0x3a>;
			};

			uart1-rts-gpio {
				rockchip,pins = <0x3 0x5 0x0 0x82>;
			};
		};

		uart2-0 {

			uart2m0-xfer {
				rockchip,pins = <0x1 0x0 0x2 0x83 0x1 0x1 0x2 0x82>;
			};
		};

		uart2-1 {

			uart2m1-xfer {
				rockchip,pins = <0x2 0x0 0x1 0x83 0x2 0x1 0x1 0x83>;
				linux,phandle = <0x3b>;
				phandle = <0x3b>;
			};
		};

		spi0-0 {

			spi0m0-clk {
				rockchip,pins = <0x2 0x8 0x1 0x83>;
			};

			spi0m0-cs0 {
				rockchip,pins = <0x2 0xb 0x1 0x83>;
			};

			spi0m0-tx {
				rockchip,pins = <0x2 0x9 0x1 0x83>;
			};

			spi0m0-rx {
				rockchip,pins = <0x2 0xa 0x1 0x83>;
			};

			spi0m0-cs1 {
				rockchip,pins = <0x2 0xc 0x1 0x83>;
			};
		};

		spi0-1 {

			spi0m1-clk {
				rockchip,pins = <0x3 0x17 0x2 0x83>;
			};

			spi0m1-cs0 {
				rockchip,pins = <0x3 0x1a 0x2 0x83>;
			};

			spi0m1-tx {
				rockchip,pins = <0x3 0x19 0x2 0x83>;
			};

			spi0m1-rx {
				rockchip,pins = <0x3 0x18 0x2 0x83>;
			};

			spi0m1-cs1 {
				rockchip,pins = <0x3 0x1b 0x2 0x83>;
			};
		};

		spi0-2 {

			spi0m2-clk {
				rockchip,pins = <0x3 0x0 0x4 0x83>;
				linux,phandle = <0x42>;
				phandle = <0x42>;
			};

			spi0m2-cs0 {
				rockchip,pins = <0x3 0x8 0x3 0x83>;
				linux,phandle = <0x45>;
				phandle = <0x45>;
			};

			spi0m2-tx {
				rockchip,pins = <0x3 0x1 0x4 0x83>;
				linux,phandle = <0x43>;
				phandle = <0x43>;
			};

			spi0m2-rx {
				rockchip,pins = <0x3 0x2 0x4 0x83>;
				linux,phandle = <0x44>;
				phandle = <0x44>;
			};
		};

		pdm-0 {

			pdmm0-clk {
				rockchip,pins = <0x2 0x12 0x2 0x82>;
				linux,phandle = <0x15>;
				phandle = <0x15>;
			};

			pdmm0-fsync {
				rockchip,pins = <0x2 0x17 0x2 0x82>;
				linux,phandle = <0x16>;
				phandle = <0x16>;
			};

			pdmm0-sdi0 {
				rockchip,pins = <0x2 0x13 0x2 0x82>;
				linux,phandle = <0x17>;
				phandle = <0x17>;
			};

			pdmm0-sdi1 {
				rockchip,pins = <0x2 0x14 0x2 0x82>;
				linux,phandle = <0x18>;
				phandle = <0x18>;
			};

			pdmm0-sdi2 {
				rockchip,pins = <0x2 0x15 0x2 0x82>;
				linux,phandle = <0x19>;
				phandle = <0x19>;
			};

			pdmm0-sdi3 {
				rockchip,pins = <0x2 0x16 0x2 0x82>;
				linux,phandle = <0x1a>;
				phandle = <0x1a>;
			};

			pdmm0-sleep {
				rockchip,pins = <0x2 0x12 0x0 0x84 0x2 0x13 0x0 0x84 0x2 0x14 0x0 0x84 0x2 0x15 0x0 0x84 0x2 0x16 0x0 0x84 0x2 0x17 0x0 0x84>;
				linux,phandle = <0x1b>;
				phandle = <0x1b>;
			};
		};

		i2s1 {

			i2s1-mclk {
				rockchip,pins = <0x2 0xf 0x1 0x82>;
			};

			i2s1-sclk {
				rockchip,pins = <0x2 0x12 0x1 0x82>;
			};

			i2s1-lrckrx {
				rockchip,pins = <0x2 0x10 0x1 0x82>;
			};

			i2s1-lrcktx {
				rockchip,pins = <0x2 0x11 0x1 0x82>;
			};

			i2s1-sdi {
				rockchip,pins = <0x2 0x13 0x1 0x82>;
			};

			i2s1-sdo {
				rockchip,pins = <0x2 0x17 0x1 0x82>;
			};

			i2s1-sdio1 {
				rockchip,pins = <0x2 0x14 0x1 0x82>;
			};

			i2s1-sdio2 {
				rockchip,pins = <0x2 0x15 0x1 0x82>;
			};

			i2s1-sdio3 {
				rockchip,pins = <0x2 0x16 0x1 0x82>;
			};

			i2s1-sleep {
				rockchip,pins = <0x2 0xf 0x0 0x84 0x2 0x10 0x0 0x84 0x2 0x11 0x0 0x84 0x2 0x12 0x0 0x84 0x2 0x13 0x0 0x84 0x2 0x14 0x0 0x84 0x2 0x15 0x0 0x84 0x2 0x16 0x0 0x84 0x2 0x17 0x0 0x84>;
			};
		};

		i2s2-0 {

			i2s2m0-mclk {
				rockchip,pins = <0x1 0x15 0x1 0x82>;
				linux,phandle = <0xd>;
				phandle = <0xd>;
			};

			i2s2m0-sclk {
				rockchip,pins = <0x1 0x16 0x1 0x82>;
				linux,phandle = <0xe>;
				phandle = <0xe>;
			};

			i2s2m0-lrckrx {
				rockchip,pins = <0x1 0x1a 0x1 0x82>;
				linux,phandle = <0x10>;
				phandle = <0x10>;
			};

			i2s2m0-lrcktx {
				rockchip,pins = <0x1 0x17 0x1 0x82>;
				linux,phandle = <0xf>;
				phandle = <0xf>;
			};

			i2s2m0-sdi {
				rockchip,pins = <0x1 0x18 0x1 0x82>;
				linux,phandle = <0x12>;
				phandle = <0x12>;
			};

			i2s2m0-sdo {
				rockchip,pins = <0x1 0x19 0x1 0x82>;
				linux,phandle = <0x11>;
				phandle = <0x11>;
			};

			i2s2m0-sleep {
				rockchip,pins = <0x1 0x15 0x0 0x84 0x1 0x16 0x0 0x84 0x1 0x1a 0x0 0x84 0x1 0x17 0x0 0x84 0x1 0x18 0x0 0x84 0x1 0x19 0x0 0x84>;
				linux,phandle = <0x13>;
				phandle = <0x13>;
			};
		};

		i2s2-1 {

			i2s2m1-mclk {
				rockchip,pins = <0x1 0x15 0x1 0x82>;
			};

			i2s2m1-sclk {
				rockchip,pins = <0x3 0x0 0x6 0x82>;
			};

			i2sm1-lrckrx {
				rockchip,pins = <0x3 0x8 0x6 0x82>;
			};

			i2s2m1-lrcktx {
				rockchip,pins = <0x3 0x8 0x4 0x82>;
			};

			i2s2m1-sdi {
				rockchip,pins = <0x3 0x2 0x6 0x82>;
			};

			i2s2m1-sdo {
				rockchip,pins = <0x3 0x1 0x6 0x82>;
			};

			i2s2m1-sleep {
				rockchip,pins = <0x1 0x15 0x0 0x84 0x3 0x0 0x0 0x84 0x3 0x8 0x0 0x84 0x3 0x2 0x0 0x84 0x3 0x1 0x0 0x84>;
			};
		};

		spdif-0 {

			spdifm0-tx {
				rockchip,pins = <0x0 0x1b 0x1 0x82>;
			};
		};

		spdif-1 {

			spdifm1-tx {
				rockchip,pins = <0x2 0x11 0x2 0x82>;
				linux,phandle = <0x14>;
				phandle = <0x14>;
			};
		};

		spdif-2 {

			spdifm2-tx {
				rockchip,pins = <0x0 0x2 0x2 0x82>;
			};
		};

		sdmmc0-0 {

			sdmmc0m0-pwren {
				rockchip,pins = <0x2 0x7 0x1 0x85>;
			};

			sdmmc0m0-gpio {
				rockchip,pins = <0x2 0x7 0x0 0x85>;
			};
		};

		sdmmc0-1 {

			sdmmc0m1-pwren {
				rockchip,pins = <0x0 0x1e 0x3 0x85>;
			};

			sdmmc0m1-gpio {
				rockchip,pins = <0x0 0x1e 0x0 0x85>;
				linux,phandle = <0x99>;
				phandle = <0x99>;
			};
		};

		sdmmc0 {

			sdmmc0-clk {
				rockchip,pins = <0x1 0x6 0x1 0x86>;
				linux,phandle = <0x69>;
				phandle = <0x69>;
			};

			sdmmc0-cmd {
				rockchip,pins = <0x1 0x4 0x1 0x85>;
				linux,phandle = <0x6a>;
				phandle = <0x6a>;
			};

			sdmmc0-dectn {
				rockchip,pins = <0x1 0x5 0x1 0x85>;
				linux,phandle = <0x6b>;
				phandle = <0x6b>;
			};

			sdmmc0-wrprt {
				rockchip,pins = <0x1 0x7 0x1 0x85>;
			};

			sdmmc0-bus1 {
				rockchip,pins = <0x1 0x0 0x1 0x85>;
			};

			sdmmc0-bus4 {
				rockchip,pins = <0x1 0x0 0x1 0x85 0x1 0x1 0x1 0x85 0x1 0x2 0x1 0x85 0x1 0x3 0x1 0x85>;
				linux,phandle = <0x6c>;
				phandle = <0x6c>;
			};

			sdmmc0-gpio {
				rockchip,pins = <0x1 0x6 0x0 0x85 0x1 0x4 0x0 0x85 0x1 0x5 0x0 0x85 0x1 0x7 0x0 0x85 0x1 0x3 0x0 0x85 0x1 0x2 0x0 0x85 0x1 0x1 0x0 0x85 0x1 0x0 0x0 0x85>;
			};
		};

		sdmmc0ext {

			sdmmc0ext-clk {
				rockchip,pins = <0x3 0x2 0x3 0x86>;
				linux,phandle = <0x7c>;
				phandle = <0x7c>;
			};

			sdmmc0ext-cmd {
				rockchip,pins = <0x3 0x0 0x3 0x85>;
				linux,phandle = <0x7b>;
				phandle = <0x7b>;
			};

			sdmmc0ext-wrprt {
				rockchip,pins = <0x3 0x3 0x3 0x85>;
			};

			sdmmc0ext-dectn {
				rockchip,pins = <0x3 0x1 0x3 0x85>;
			};

			sdmmc0ext-bus1 {
				rockchip,pins = <0x3 0x4 0x3 0x85>;
			};

			sdmmc0ext-bus4 {
				rockchip,pins = <0x3 0x4 0x3 0x85 0x3 0x5 0x3 0x85 0x3 0x6 0x3 0x85 0x3 0x7 0x3 0x85>;
				linux,phandle = <0x7a>;
				phandle = <0x7a>;
			};

			sdmmc0ext-gpio {
				rockchip,pins = <0x3 0x0 0x0 0x85 0x3 0x1 0x0 0x85 0x3 0x2 0x0 0x85 0x3 0x3 0x0 0x85 0x3 0x4 0x0 0x85 0x3 0x5 0x0 0x85 0x3 0x6 0x0 0x85 0x3 0x7 0x0 0x85>;
			};
		};

		sdmmc1 {

			sdmmc1-clk {
				rockchip,pins = <0x1 0xc 0x1 0x87>;
			};

			sdmmc1-cmd {
				rockchip,pins = <0x1 0xd 0x1 0x88>;
			};

			sdmmc1-pwren {
				rockchip,pins = <0x1 0x12 0x1 0x88>;
			};

			sdmmc1-wrprt {
				rockchip,pins = <0x1 0x14 0x1 0x88>;
			};

			sdmmc1-dectn {
				rockchip,pins = <0x1 0x13 0x1 0x88>;
			};

			sdmmc1-bus1 {
				rockchip,pins = <0x1 0xe 0x1 0x88>;
			};

			sdmmc1-bus4 {
				rockchip,pins = <0x1 0xe 0x1 0x88 0x1 0xf 0x1 0x88 0x1 0x10 0x1 0x88 0x1 0x11 0x1 0x88>;
			};

			sdmmc1-gpio {
				rockchip,pins = <0x1 0xc 0x0 0x85 0x1 0xd 0x0 0x85 0x1 0xe 0x0 0x85 0x1 0xf 0x0 0x85 0x1 0x10 0x0 0x85 0x1 0x11 0x0 0x85 0x1 0x12 0x0 0x85 0x1 0x13 0x0 0x85 0x1 0x14 0x0 0x85>;
			};
		};

		emmc {

			emmc-clk {
				rockchip,pins = <0x3 0x15 0x2 0x89>;
				linux,phandle = <0x6e>;
				phandle = <0x6e>;
			};

			emmc-cmd {
				rockchip,pins = <0x3 0x13 0x2 0x8a>;
				linux,phandle = <0x6f>;
				phandle = <0x6f>;
			};

			emmc-pwren {
				rockchip,pins = <0x3 0x16 0x2 0x82>;
			};

			emmc-rstnout {
				rockchip,pins = <0x3 0x14 0x2 0x82>;
			};

			emmc-bus1 {
				rockchip,pins = <0x0 0x7 0x2 0x8a>;
			};

			emmc-bus4 {
				rockchip,pins = <0x0 0x7 0x2 0x8a 0x2 0x1c 0x2 0x8a 0x2 0x1d 0x2 0x8a 0x2 0x1e 0x2 0x8a>;
			};

			emmc-bus8 {
				rockchip,pins = <0x0 0x7 0x2 0x8a 0x2 0x1c 0x2 0x8a 0x2 0x1d 0x2 0x8a 0x2 0x1e 0x2 0x8a 0x2 0x1f 0x2 0x8a 0x3 0x10 0x2 0x8a 0x3 0x11 0x2 0x8a 0x3 0x12 0x2 0x8a>;
				linux,phandle = <0x70>;
				phandle = <0x70>;
			};
		};

		pwm0 {

			pwm0-pin {
				rockchip,pins = <0x2 0x4 0x1 0x82>;
				linux,phandle = <0x46>;
				phandle = <0x46>;
			};
		};

		pwm1 {

			pwm1-pin {
				rockchip,pins = <0x2 0x5 0x1 0x82>;
				linux,phandle = <0x47>;
				phandle = <0x47>;
			};
		};

		pwm2 {

			pwm2-pin {
				rockchip,pins = <0x2 0x6 0x1 0x82>;
				linux,phandle = <0x48>;
				phandle = <0x48>;
			};
		};

		pwmir {

			pwmir-pin {
				rockchip,pins = <0x2 0x2 0x1 0x82>;
				linux,phandle = <0x49>;
				phandle = <0x49>;
			};
		};

		gmac-1 {

			rgmiim1-pins {
				rockchip,pins = <0x1 0xc 0x2 0x89 0x1 0xd 0x2 0x8b 0x1 0x13 0x2 0x8b 0x1 0x19 0x2 0x89 0x1 0x15 0x2 0x8b 0x1 0x16 0x2 0x8b 0x1 0x17 0x2 0x8b 0x1 0xa 0x2 0x8b 0x1 0xb 0x2 0x8b 0x1 0x8 0x2 0x89 0x1 0x9 0x2 0x89 0x1 0xe 0x2 0x8b 0x1 0xf 0x2 0x8b 0x1 0x10 0x2 0x89 0x1 0x11 0x2 0x89 0x0 0x8 0x1 0x82 0x0 0xc 0x1 0x82 0x0 0x18 0x1 0x82 0x0 0x10 0x1 0x82 0x0 0x11 0x1 0x82 0x0 0x17 0x1 0x82 0x0 0x16 0x1 0x82>;
				linux,phandle = <0x74>;
				phandle = <0x74>;
			};

			rmiim1-pins {
				rockchip,pins = <0x1 0x13 0x2 0x8b 0x1 0x19 0x2 0x89 0x1 0x15 0x2 0x8b 0x1 0x18 0x2 0x8b 0x1 0x16 0x2 0x8b 0x1 0x17 0x2 0x8b 0x1 0xa 0x2 0x8b 0x1 0xb 0x2 0x8b 0x1 0x8 0x2 0x89 0x1 0x9 0x2 0x89 0x0 0xb 0x1 0x82 0x0 0xc 0x1 0x82 0x0 0x18 0x1 0x82 0x0 0x13 0x1 0x82 0x0 0x10 0x1 0x82 0x0 0x11 0x1 0x82>;
			};
		};

		gmac2phy {

			fephyled-speed100 {
				rockchip,pins = <0x0 0x1f 0x1 0x82>;
			};

			fephyled-speed10 {
				rockchip,pins = <0x0 0x1e 0x1 0x82>;
			};

			fephyled-duplex {
				rockchip,pins = <0x0 0x1e 0x2 0x82>;
			};

			fephyled-rxm0 {
				rockchip,pins = <0x0 0x1d 0x1 0x82>;
			};

			fephyled-txm0 {
				rockchip,pins = <0x0 0x1d 0x2 0x82>;
			};

			fephyled-linkm0 {
				rockchip,pins = <0x0 0x1c 0x1 0x82>;
			};

			fephyled-rxm1 {
				rockchip,pins = <0x2 0x19 0x2 0x82>;
				linux,phandle = <0x75>;
				phandle = <0x75>;
			};

			fephyled-txm1 {
				rockchip,pins = <0x2 0x19 0x3 0x82>;
			};

			fephyled-linkm1 {
				rockchip,pins = <0x2 0x18 0x2 0x82>;
				linux,phandle = <0x76>;
				phandle = <0x76>;
			};
		};

		tsadc_pin {

			tsadc-int {
				rockchip,pins = <0x2 0xd 0x2 0x82>;
			};

			tsadc-gpio {
				rockchip,pins = <0x2 0xd 0x0 0x82>;
			};
		};

		hdmi_pin {

			hdmi-cec {
				rockchip,pins = <0x0 0x3 0x1 0x82>;
				linux,phandle = <0x5b>;
				phandle = <0x5b>;
			};

			hdmi-hpd {
				rockchip,pins = <0x0 0x4 0x1 0x8c>;
				linux,phandle = <0x5d>;
				phandle = <0x5d>;
			};
		};

		cif-0 {

			dvp-d2d9-m0 {
				rockchip,pins = <0x3 0x4 0x2 0x82 0x3 0x5 0x2 0x82 0x3 0x6 0x2 0x82 0x3 0x7 0x2 0x82 0x3 0x8 0x2 0x82 0x3 0x9 0x2 0x82 0x3 0xa 0x2 0x82 0x3 0xb 0x2 0x82 0x3 0x1 0x2 0x82 0x3 0x0 0x2 0x82 0x3 0x3 0x2 0x82 0x3 0x2 0x2 0x82>;
			};
		};

		cif-1 {

			dvp-d2d9-m1 {
				rockchip,pins = <0x3 0x4 0x2 0x82 0x3 0x5 0x2 0x82 0x3 0x6 0x2 0x82 0x3 0x7 0x2 0x82 0x3 0x8 0x2 0x82 0x2 0x10 0x4 0x82 0x2 0x11 0x4 0x82 0x2 0x12 0x4 0x82 0x3 0x1 0x2 0x82 0x3 0x0 0x2 0x82 0x2 0xf 0x4 0x82 0x3 0x2 0x2 0x82>;
			};
		};

		pmic {

			pmic-int-l {
				rockchip,pins = <0x2 0x6 0x0 0x83>;
				linux,phandle = <0x3f>;
				phandle = <0x3f>;
			};
		};

		sdio-pwrseq {

			wifi-enable-h {
				rockchip,pins = <0x3 0x8 0x0 0x82>;
				linux,phandle = <0x8e>;
				phandle = <0x8e>;
			};
		};

		usb {

			host-vbus-drv {
				rockchip,pins = <0x0 0x0 0x0 0x82>;
				linux,phandle = <0x97>;
				phandle = <0x97>;
			};

			otg-vbus-drv {
				rockchip,pins = <0x0 0x1b 0x0 0x82>;
				linux,phandle = <0x98>;
				phandle = <0x98>;
			};
		};

		wireless-bluetooth {

			uart0-gpios {
				rockchip,pins = <0x1 0xa 0x0 0x82>;
				linux,phandle = <0x9c>;
				phandle = <0x9c>;
			};
		};
	};

	chosen {
		bootargs = "earlyprintk=uart8250-32bit,0xff130000";
	};

	fiq-debugger {
		compatible = "rockchip,fiq-debugger";
		rockchip,serial-id = <0x2>;
		rockchip,signal-irq = <0x9f>;
		rockchip,wake-irq = <0x0>;
		rockchip,irq-mode-enable = <0x0>;
		rockchip,baudrate = <0x16e360>;
		interrupts = <0x0 0x7f 0x8>;
		status = "okay";
	};

	reserved-memory {
		#address-cells = <0x2>;
		#size-cells = <0x2>;
		ranges;

		drm-logo@00000000 {
			compatible = "rockchip,drm-logo";
			reg = <0x0 0xfcc00000 0x0 0xbddc36>;
			linux,phandle = <0x62>;
			phandle = <0x62>;
		};

		secure-memory@20000000 {
			compatible = "rockchip,secure-memory";
			reg = <0x0 0x20000000 0x0 0x0>;
			linux,phandle = <0x63>;
			phandle = <0x63>;
		};

		ramoops@68000000 {
			reg = <0x0 0x110000 0x0 0xf0000>;
			linux,phandle = <0x8d>;
			phandle = <0x8d>;
		};
	};

	ramoops {
		compatible = "ramoops";
		record-size = <0x0 0x20000>;
		console-size = <0x0 0x80000>;
		ftrace-size = <0x0 0x0>;
		pmsg-size = <0x0 0x50000>;
		memory-region = <0x8d>;
	};

	sk-keypad {
		compatible = "rockchip,key";

		power-key {
			gpios = <0x3e 0x15 0x1>;
			linux,code = <0x74>;
			label = "power";
			gpio-key,wakeup;
		};
	};

	external-gmac-clock {
		compatible = "fixed-clock";
		clock-frequency = <0x7735940>;
		clock-output-names = "gmac_clkin";
		#clock-cells = <0x0>;
		linux,phandle = <0x73>;
		phandle = <0x73>;
	};

	sdio-pwrseq {
		compatible = "mmc-pwrseq-simple";
		pinctrl-names = "default";
		pinctrl-0 = <0x8e>;
		reset-gpios = <0x8f 0x8 0x1>;
		linux,phandle = <0x79>;
		phandle = <0x79>;
	};

	sound {
		compatible = "simple-audio-card";
		simple-audio-card,format = "i2s";
		simple-audio-card,mclk-fs = <0x100>;
		simple-audio-card,name = "rockchip,rk3328";

		simple-audio-card,cpu {
			sound-dai = <&i2s1>;
		};

		simple-audio-card,codec {
			sound-dai = <0x91>;
		};
	};

	hdmi-sound {
		compatible = "simple-audio-card";
		simple-audio-card,format = "i2s";
		simple-audio-card,mclk-fs = <128>;
		simple-audio-card,name = "rockchip,hdmi";

		simple-audio-card,cpu {
			sound-dai = <&i2s0>;
		};

		simple-audio-card,codec {
			sound-dai = <0x93>;
		};
	};

	spdif-sound {
		compatible = "simple-audio-card";
		simple-audio-card,name = "rockchip,spdif";

		simple-audio-card,cpu {
			sound-dai = <&spdif>;
		};

		simple-audio-card,codec {
			sound-dai = <0x95>;
		};
	};

	spdif-out {
		compatible = "linux,spdif-dit";
		#sound-dai-cells = <0x0>;
		linux,phandle = <0x95>;
		phandle = <0x95>;
	};

	host-vbus-regulator {
		compatible = "regulator-fixed";
		gpio = <0x96 0x0 0x0>;
		pinctrl-names = "default";
		pinctrl-0 = <0x97>;
		regulator-name = "vcc_host_vbus";
		regulator-min-microvolt = <0x4c4b40>;
		regulator-max-microvolt = <0x4c4b40>;
		enable-active-high;
		linux,phandle = <0x68>;
		phandle = <0x68>;
	};

	otg-vbus-regulator {
		compatible = "regulator-fixed";
		gpio = <0x96 0x1b 0x0>;
		pinctrl-names = "default";
		pinctrl-0 = <0x98>;
		regulator-name = "vcc_otg_vbus";
		regulator-min-microvolt = <0x4c4b40>;
		regulator-max-microvolt = <0x4c4b40>;
		enable-active-high;
		linux,phandle = <0x66>;
		phandle = <0x66>;
	};

	vcc-phy-regulator {
		compatible = "regulator-fixed";
		regulator-name = "vcc_phy";
		regulator-always-on;
		regulator-boot-on;
		linux,phandle = <0x71>;
		phandle = <0x71>;
	};

	sdmmc-regulator {
		compatible = "regulator-fixed";
		gpio = <0x96 0x1e 0x1>;
		pinctrl-names = "default";
		pinctrl-0 = <0x99>;
		regulator-name = "vcc_sd";
		regulator-min-microvolt = <0x325aa0>;
		regulator-max-microvolt = <0x325aa0>;
		vin-supply = <&vcc_io>;
		linux,phandle = <0x6d>;
		phandle = <0x6d>;
	};

	wireless-bluetooth {
		compatible = "bluetooth-platdata";
		clocks = <&rk805 0x1>;
		clock-names = "ext_clock";
		uart_rts_gpios = <0x72 0xa 0x1>;
		pinctrl-names = "default", "rts_gpio";
		pinctrl-0 = <0x9b>;
		pinctrl-1 = <0x9c>;
		BT,reset_gpio = <0x72 0x15 0x0>;
		BT,wake_gpio = <0x72 0x17 0x0>;
		BT,wake_host_irq = <0x72 0x1a 0x0>;
		status = "okay";
	};

	wireless-wlan {
		compatible = "wlan-platdata";
		rockchip,grf = <&grf>;
		wifi_chip_type = [00];
		sdio_vref = <0xce4>;
		#WIFI,poweren_gpio = <0x8f 0x8 0x0>;
		WIFI,host_wake_irq = <0x8f 0x1 0x0>;
		status = "okay";
	};

	leds {
		compatible = "gpio-leds";

		power-green {
			gpios = <&rk805 0x0 0x0>;
			linux,default-trigger = "none";
			default-state = "on";
			mode = <0x23>;
		};
	};
};
